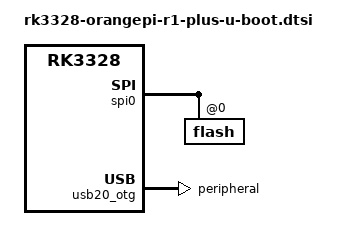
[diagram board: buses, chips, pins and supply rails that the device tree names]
// SPDX-License-Identifier: GPL-2.0-or-later
/*
 * (C) Copyright 2018-2019 Rockchip Electronics Co., Ltd
 * (C) Copyright 2020 David Bauer
 */

#include "rk3328-u-boot.dtsi"
#include "rk3328-sdram-ddr4-666.dtsi"

&spi0 {
	flash@0 {
		bootph-pre-ram;
		bootph-some-ram;
	};
};

&spi0m2_clk {
	bootph-pre-ram;
	bootph-some-ram;
};

&spi0m2_cs0 {
	bootph-pre-ram;
	bootph-some-ram;
};

&spi0m2_rx {
	bootph-pre-ram;
	bootph-some-ram;
};

&spi0m2_tx {
	bootph-pre-ram;
	bootph-some-ram;
};

&usb20_otg {
	dr_mode = "peripheral";
};

&vcc_sd {
	bootph-pre-ram;
};
